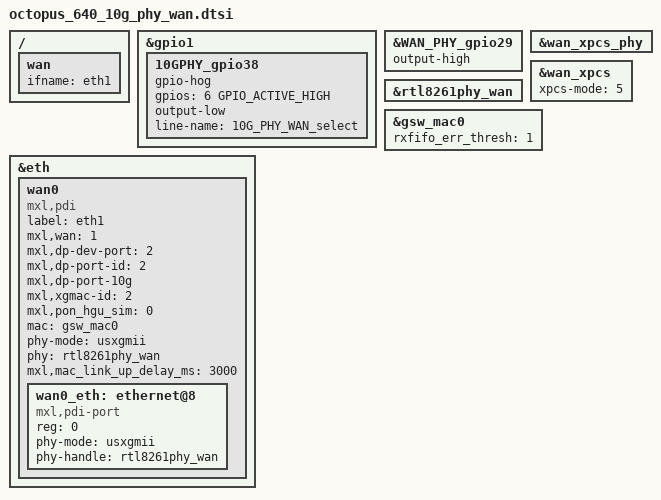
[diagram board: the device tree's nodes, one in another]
// SPDX-License-Identifier: GPL-2.0
/*
 * Copyright (C) 2024-2025 MaxLinear, Inc.
 */

/* Select 10G PHY WAN */
&gpio1 {
	10GPHY_gpio38 {
		gpio-hog;
		gpios = <6 GPIO_ACTIVE_HIGH>;
		output-low;
		line-name = "10G_PHY_WAN_select";
	};
};

/* Enable 10G PHY WAN */
&WAN_PHY_gpio29   {
	/delete-property/ output-low;
	output-high;
};

/ {
	wan {
		ifname = "eth1";
	};
};

/* WAN XPCS PHY */
&wan_xpcs_phy {
	status = "okay";
};

&wan_xpcs {
	status = "okay";
	xpcs-mode = <5>; /* USXGMII */
};

&rtl8261phy_wan {
	status = "okay";
};

&gsw_mac0 {
	rxfifo_err_thresh = <1>;
};

&eth {
	wan0 {
		status = "okay";

		#address-cells = <1>;
		#size-cells = <0>;
		label = "eth1";
		compatible = "mxl,pdi";
		mxl,wan = <1>;
		mxl,dp-dev-port = <2>;
		mxl,dp-port-id = <2>;
		mxl,dp-port-10g;
		mxl,xgmac-id = <2>;
		mxl,pon_hgu_sim = <0>;
		mac = <&gsw_mac0>;
		phy-mode = "usxgmii";
		phy = <&rtl8261phy_wan>;
		mxl,mac_link_up_delay_ms = <3000>;

		wan0_eth: ethernet@8 {
			compatible = "mxl,pdi-port";
			reg = <0>;
			phy-mode = "usxgmii";
			phy-handle = <&rtl8261phy_wan>;
		};
	};
};
